# nrf7140_wificore register map
Vendor: Nordic Semiconductor; Series: nRF71; File version: 1
Registers are 32-bit, read-write, reset 0x0 unless marked. A register's access mark holds for its fields unless they carry their own. Offsets are from the block's base; [hi:lo] are bit positions; lines under a group give offsets from that group; {n}, {i} and the like mark numbered series; 'fields as' and 'values as' point back to an identical list; <NAME> marks a mode.

## RPUPHY (part 7 of 8) — WIFICore RPU PHY peripherals
Base 0x48080000; alternate view of RPUMAC
0x11000 TXSCP group — Unspecified
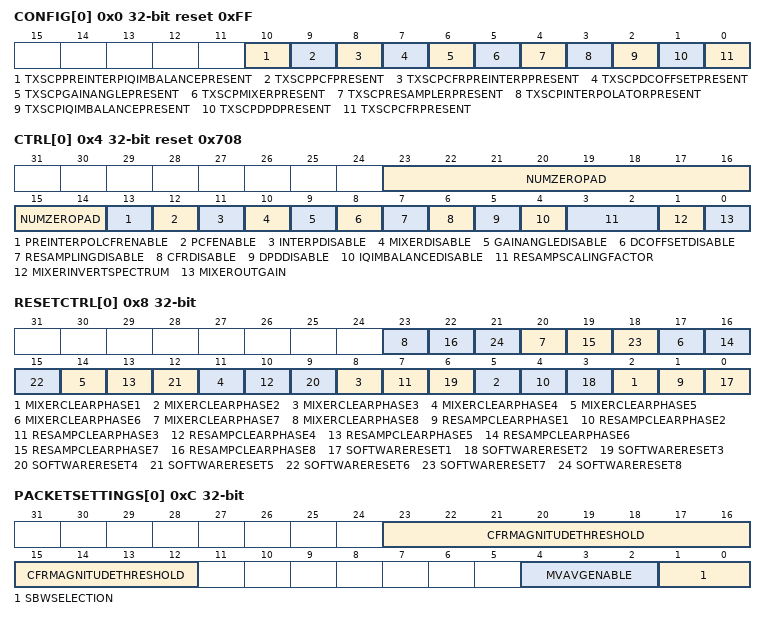
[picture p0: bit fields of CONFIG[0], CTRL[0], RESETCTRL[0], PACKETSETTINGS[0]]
  {0x0+4j} CONFIG[{j}] (j=0..0) ro reset 0xFF — Description collection: TXSCP CONFIG
    [10] TXSCPPREINTERPIQIMBALANCEPRESENT — This is a read-only field. Value read out indicates the presence of the pre interpolator IQ Imbalance block in the TX SCP.0: Pre interpolator IQ Imbalance not present.1: Pre interpolator IQ Imbalance present.Writing to field would not change its value.
    [9] TXSCPPCFPRESENT — This is a read-only field. Value read out indicates the presence of the PCF block in the TX SCP.0: PCF not present.1: PCF present.Writing to field would not change its value.
    [8] TXSCPCFRPREINTERPPRESENT — This is a read-only field. Value read out indicates the presence of the pre interpolator block in the TX SCP.0: Pre interpolator not present.1: Pre interpolator present.Writing to field would not change its value.
    [7] TXSCPDCOFFSETPRESENT — This is a read-only field. Value read out indicates the presence of the DC Offset block in the TX SCP.0: DC Offset not present.1: DC Offset present.Writing to field would not change its value.
    [6] TXSCPGAINANGLEPRESENT — This is a read-only field. Value read out indicates the presence of the Gain Angle block in the TX SCP.0: Gain Angle not present.1: Gain Angle present.Writing to field would not change its value.
    [5] TXSCPMIXERPRESENT — This is a read-only field. Value read out indicates the presence of the Mixer block in the TX SCP.0: Mixer not present.1: Mixer present.Writing to field would not change its value.
    [4] TXSCPRESAMPLERPRESENT — This is a read-only field. Value read out indicates the presence of the Resampler block in the TX SCP.0: Resampler not present.1: Resampler present.Writing to field would not change its value.
    [3] TXSCPINTERPOLATORPRESENT — This is a read-only field. Value read out indicates the presence of the Interpolator block in the TX SCP.0: Interpolator not present.1: Interpolator present.Writing to field would not change its value.
    [2] TXSCPIQIMBALANCEPRESENT — This is a read-only field. Value read out indicates the presence of the IQ imbalance block in the TX SCP.0: IQ imbalance not present.1: IQ imbalance present.Writing to field would not change its value.
    [1] TXSCPDPDPRESENT — This is a read-only field. Value read out indicates the presence of the DPD block in the TX SCP.0: DPD not present.1: DPD present.Writing to field would not change its value.
    [0] TXSCPCFRPRESENT — This is a read-only field. Value read out indicates the presence of the CFR block in the TX SCP.0: CFR not present.1: CFR present.Writing to field would not change its value.
  {0x4+4j} CTRL[{j}] (j=0..0) reset 0x708 — Description collection: TXSCP CTRL
    [23:14] NUMZEROPAD — Number of padding zeros to add to the input at the end of the packet.
    [13] PREINTERPOLCFRENABLE — Used to set the bypass mode of the pre interpolator CFR in TX-SCP block:
      0=Pre interpolator CFR is powered down and data passes around it unaltered; 1=PreInterpolatorCfrIs1 (Pre interpolator CFR is active.)
    [12] PCFENABLE — Used to set the bypass mode of the PCF in TX-SCP block:
      0=PCF is powered down and data passes around it unaltered; 1=PcfIsActive
    [11] INTERPDISABLE — Used to set the bypass mode of the interpolator in TX-SCP block:
      0=Interpolator is active (Interpolation factor I = 2); 1=Interpolator is powered down. Data passes around it unaltered (Interpolation factor I = 1).
    [10] MIXERDISABLE — Used to set the bypass mode of the Mixer block:
      0=MixerBlockIsActive; 1=Mixer block is powered down and data passes around it unaltered
    [9] GAINANGLEDISABLE — Used to set the bypass mode of the Gain Angle block:
      0=Gain Angle block is active; 1=Gain Angle block is powered down and data passes around it unaltered
    [8] DCOFFSETDISABLE — Used to set the bypass mode of the DC Offset block:
      0=DC Offset block is active; 1=DC Offset block is powered down and data passes around it unaltered
    [7] RESAMPLINGDISABLE — Used to set the bypass mode for the resampling operation:
      0=Resampling operation active; 1=Resampling operation powered down. The input data to the resampler is sent unaltered to the Mixer.
    [6] CFRDISABLE — Used to set the bypass mode of the CFR block:
      0=CfrIsActive; 1=CFR is powered down and data passes around it unaltered
    [5] DPDDISABLE — Used to set the bypass mode of the DPD block:
      0=DpdIsActive; 1=DPD is powered down and data passes around it unaltered
    [4] IQIMBALANCEDISABLE — Used to set the bypass mode of the IQ imbalance compensation block:
      0=IQ imbalance compensation is active; 1=IQ imbalance compenstation block is powered down and data passes around it unaltered
    [3:2] RESAMPSCALINGFACTOR — X8 output scaled by a factor of:
      0=025; 1=050; 2=100; 3=200
    [1] MIXERINVERTSPECTRUM — Selects Mixer spectrum inversion:0: The mixer output spectrum is not inverted.1: The mixer output spectrum is inverted by swapping I and Q.The mixer design under normal operation inverts the output I and Q samples even if this field is set to 0. To re-invert set field to 1.Relevant when MIXER_DISABLE = 0.
    [0] MIXEROUTGAIN — Selects Mixer output gain:0: Gain of 1.0 is applied to the output of Mixer rotator (default).1: Gain of 2.0 is applied to the output of Mixer rotator (used to compensate for 0.5 gain in real input mode).Relevant when MIXER_DISABLE = 0.
  {0x8+4j} RESETCTRL[{j}] (j=0..0) — Description collection: TXSCP RESET CTRL
    [3n-1] MIXERCLEARPHASE{n} (n=1..8) — Clears Mixer_{n} phase:0: Mixer phase accumulators run normally.1: Mixer phase accumulators are forced to zero.Relevant when MIXER_DISABLE = 0.
    [3n-2] RESAMPCLEARPHASE{n} (n=1..8) — Clears Resampler_{n} phase:0: Resampler phase accumulators run normally.1: Resampler phase accumulators are forced to zero.Relevant when RESAMPLING_DISABLE = 0.
    [3n-3] SOFTWARERESET{n} (n=1..8) — Software reset for TX-SCP{n}.
      0=NormalOperation; 1=ResetAsserted
  {0xC+4j} PACKETSETTINGS[{j}] (j=0..0) — Description collection: TXSCP PACKET SETTINGS
    [23:12] CFRMAGNITUDETHRESHOLD — Clipping threshold for CFR module with CORDIC gain compensated i.e A/gain_codic
    [4:2] MVAVGENABLE — Used to enable the post-resampler moving average filter:0: post-RS filter is powered down and data passes around it unaltered.1: post-RS moving average filter with 2 tap is enabled.2: post-RS moving average filter with 4 tap is enabled.3: post-RS moving average filter with 8 tap is enabled.4: post-RS moving average filter with 12 tap is enabled.5: post-RS moving average filter with 16 tap is enabled.6-7: Reserved.
    [1:0] SBWSELECTION — Represents the index of SBW parameter set. This index is used to select the SBW parametersfrom one of the four sets.
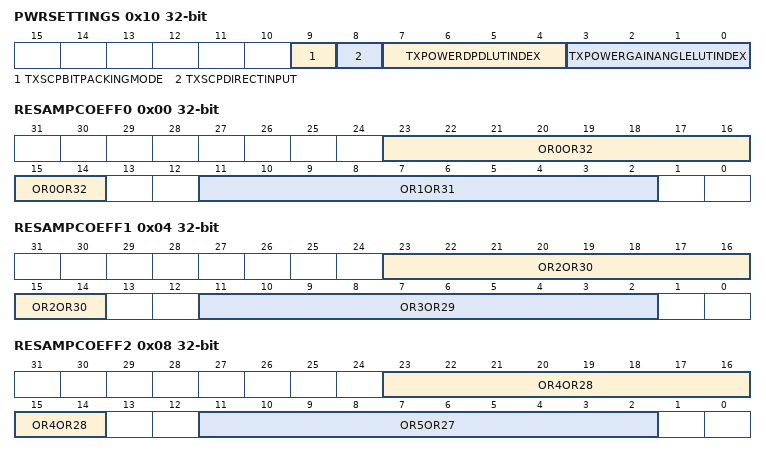
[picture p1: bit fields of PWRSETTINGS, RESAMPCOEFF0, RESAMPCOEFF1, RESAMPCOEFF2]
  0x10 PWRSETTINGS — TXSCP PWR SETTINGS
    [9] TXSCPBITPACKINGMODE — In packing mode, Converts 12-bit real and img phase inputs (at in[15:4]) to a 24-bit output with real in out[23:12] and img in out[11:0]
      0=StandardMode; 1=PackingMode
    [8] TXSCPDIRECTINPUT — Selects whether TXSCP input comes from previous pipeline stage or EDC (tbus).
      0=Tbus; 1=Direct
    [7:4] TXPOWERDPDLUTINDEX — TX power index of DPD LUT of TXSCP. This index is used to pick power dependent DPD coefficients from the DPD LUT.
    [3:0] TXPOWERGAINANGLELUTINDEX — TX power index of Gain Angle LUT of TXSCP. This index is used to pick power dependent gain/angle coefficients fromthe Gain Angle LUT.
  {0x14+0x24*j} TXSCPRESAMPCOEFF[{j}] (j=0..0) group — Unspecified
    0x00 RESAMPCOEFF0 — Description cluster: TXSCP RESAMP COEFF0
      [23:14] OR0OR32 — Coefficient of resampler filter in 2's complement format with range -1 to +1.Relevant when RESAMPLING_DISABLE = 0.
      [11:2] OR1OR31 — Coefficient of resampler filter in 2's complement format with range -1 to +1.Relevant when RESAMPLING_DISABLE = 0.
    0x04 RESAMPCOEFF1 — Description cluster: TXSCP RESAMP COEFF1
      [23:14] OR2OR30 — Coefficient of resampler filter in 2's complement format with range -1 to +1.Relevant when RESAMPLING_DISABLE = 0.
      [11:2] OR3OR29 — Coefficient of resampler filter in 2's complement format with range -1 to +1.Relevant when RESAMPLING_DISABLE = 0.
    0x08 RESAMPCOEFF2 — Description cluster: TXSCP RESAMP COEFF2
      [23:14] OR4OR28 — Coefficient of resampler filter in 2's complement format with range -1 to +1.Relevant when RESAMPLING_DISABLE = 0.
      [11:2] OR5OR27 — Coefficient of resampler filter in 2's complement format with range -1 to +1.Relevant when RESAMPLING_DISABLE = 0.
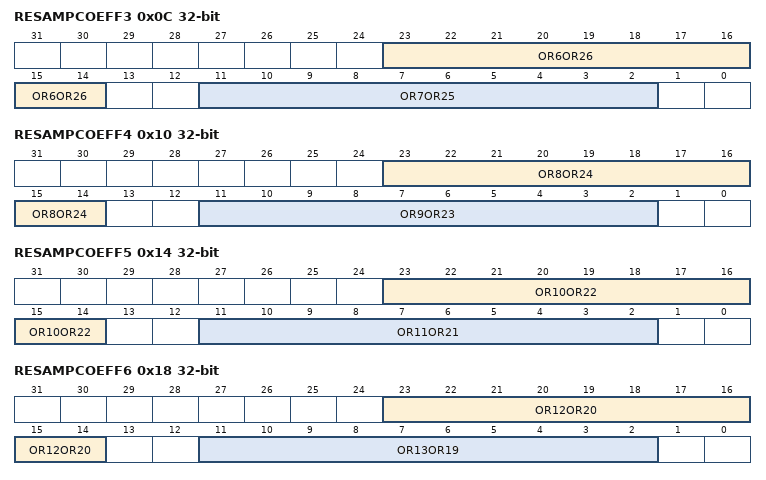
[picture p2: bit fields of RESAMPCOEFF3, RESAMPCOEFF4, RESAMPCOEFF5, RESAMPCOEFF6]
    0x0C RESAMPCOEFF3 — Description cluster: TXSCP RESAMP COEFF3
      [23:14] OR6OR26 — Coefficient of resampler filter in 2's complement format with range -1 to +1.Relevant when RESAMPLING_DISABLE = 0.
      [11:2] OR7OR25 — Coefficient of resampler filter in 2's complement format with range -1 to +1.Relevant when RESAMPLING_DISABLE = 0.
    0x10 RESAMPCOEFF4 — Description cluster: TXSCP RESAMP COEFF4
      [23:14] OR8OR24 — Coefficient of resampler filter in 2's complement format with range -1 to +1.Relevant when RESAMPLING_DISABLE = 0.
      [11:2] OR9OR23 — Coefficient of resampler filter in 2's complement format with range -1 to +1.Relevant when RESAMPLING_DISABLE = 0.
    0x14 RESAMPCOEFF5 — Description cluster: TXSCP RESAMP COEFF5
      [23:14] OR10OR22 — Coefficient of resampler filter in 2's complement format with range -1 to +1.Relevant when RESAMPLING_DISABLE = 0.
      [11:2] OR11OR21 — Coefficient of resampler filter in 2's complement format with range -1 to +1.Relevant when RESAMPLING_DISABLE = 0.
    0x18 RESAMPCOEFF6 — Description cluster: TXSCP RESAMP COEFF6
      [23:14] OR12OR20 — Coefficient of resampler filter in 2's complement format with range -1 to +1.Relevant when RESAMPLING_DISABLE = 0.
      [11:2] OR13OR19 — Coefficient of resampler filter in 2's complement format with range -1 to +1.Relevant when RESAMPLING_DISABLE = 0.
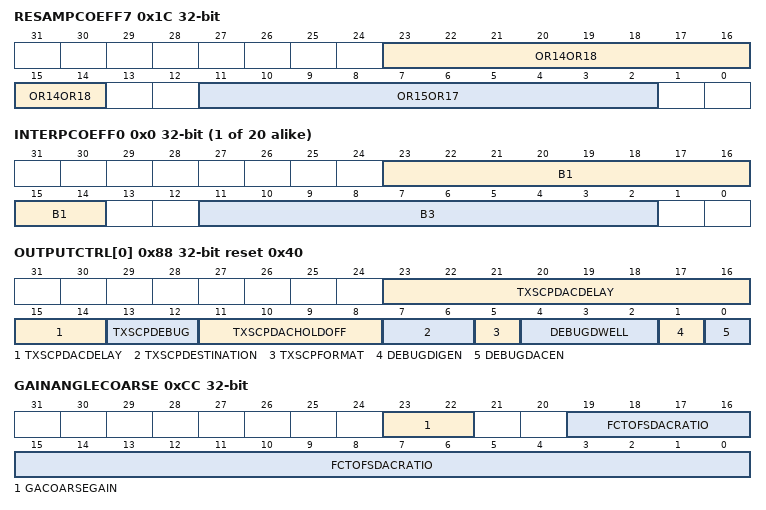
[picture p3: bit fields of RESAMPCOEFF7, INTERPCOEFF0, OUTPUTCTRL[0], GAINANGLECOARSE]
    0x1C RESAMPCOEFF7 — Description cluster: TXSCP RESAMP COEFF7
      [23:14] OR14OR18 — Coefficient of resampler filter in 2's complement format with range -1 to +1.Relevant when RESAMPLING_DISABLE = 0.
      [11:2] OR15OR17 — Coefficient of resampler filter in 2's complement format with range -1 to +1.Relevant when RESAMPLING_DISABLE = 0.
    0x20 RESAMPCOEFF8 — Description cluster: TXSCP RESAMP COEFF8
      [23:14] OR16 — Coefficient of resampler filter in 2's complement format with range -1 to +1.Relevant when RESAMPLING_DISABLE = 0.
  {0x38+0x14*j} TXSCPINTERPCOEFF[{j}] (j=0..3) group — Unspecified
    {0x0+4k} INTERPCOEFF{k} (k=0..4) — Description cluster: TXSCP INTERP COEFF{k}
      [23:14] B{4k+1} — Coefficient of interpolation filter in 2's complement format with range -1 to +1.Relevant when RESAMPLING_DISABLE = 0.
      [11:2] B{4k+3} — Coefficient of interpolation filter in 2's complement format with range -1 to +1.Relevant when RESAMPLING_DISABLE = 0.
  {0x88+4j} OUTPUTCTRL[{j}] (j=0..0) reset 0x40 — Description collection: TXSCP OUTPUT CTRL
    [23:14] TXSCPDACDELAY — Specifies the number of DAC clock cycles to delay the DAC output after a reset.
    [13:12] TXSCPDEBUG — Enable flow control debug registers TXSCP_SAMPLE_I_EXT and TXSCP_SAMPLE_Q_EXT
      0=Disabled; 1=ValidEnable; 2=Sticky(Valid), Sticky(Enable); 3=Valid & Enable, Sticky(Valid & Enable)
    [11:8] TXSCPDACHOLDOFF — Specifies the number of DAC clock cycles to hold-off the DAC output to allow the synchroniser to fill.
    [7:6] TXSCPDESTINATION — Selects the destination of the resampler output:
      0=Destination is TXSCP TBus Rd port; 1=Destination is on-board DAC; 2=Destination is TXSCP_SAMPLE register; 3=Reserve (This is reserved.)
    [5] TXSCPFORMAT — Specifies the output sample format as follows:
      0=2SComplementSamples; 1=OffsetBinarySamples
    [4:2] DEBUGDWELL — Specifies the number of times that each output sample is repeated.If the output sequence is A, B, C, D, ... then the DAC/Debug sample sequence is :DWELL=0 :A, B, C, D, ...DWELL=1 :A, A, B, B, C, C, D, D,...' ' ' ''DWELL=7 :A, A,A,A, A,A,A,A, B, B, B, ,...
    [1] DEBUGDIGEN — Enables the digital debug port:
      0=The digital debug output port is disabled; 1=TheDigitalDebugOutpu1 (The digital debug output port is enabled.)
    [0] DEBUGDACEN — Enables the DAC port:Note For the DAC output port to operate correctly, DBG_DIGEN must be set to 0.
      0=The DAC output port is disabled; 1=The DAC output port is enabled
  {0x8C+0x10*j} TXSCPSBWPARAM[{j}] (j=0..3) group — Unspecified
    0x00 BASEVAL reset 0x800000 — Description cluster: TXSCP BASE VAL
      [23:21] TXSCPBASE — Peripheral resampling factor base. This is an unsigned value which is combined with the 2's complement TXSCP_CONTROL to generate the 26-bit control FsO:FsO = (TXSCP_BASE << 23) + TXSCP_CONTROLFsO is the sample conversion ratio (I / O) used in the requirements section of the TX-SCP. FsO is an unsigned number, where the full-scale value represents a ratio of 1.999999.In normal operation, FsO is expected to take values in the range 0.0 to 1.9999. The larger number range provided here may be useful for system testing.Note: To convert a ratio into the 26-bit FsO, multiply by 2^25.Relevant when RESAMPLING_DISABLE = 0.
    0x04 FACTORVAL — Description cluster: TXSCP FACTOR VAL
      [23:0] TXSCPCONTROL — Resampling factor control. This is a 2's complement value which is combined with TXSCP_BASE to generate the 28-bit control FsO:FsO = (TXSCP_BASE << 23) + TXSCP_CONTROLRelevant when RESAMPLING_DISABLE = 0.
    0x08 MIXERLOBASE — Description cluster: TXSCP MIXER LO BASE
      [23:21] MIXLOBASE — Local Oscillator base. This is a 2's complement value which is combined with LO_CONTROL to generate the 26-bit control Fc:Fc = (LO_BASE << 23) + LO_CONTROLFc is in 2's complement signed format where its value represents numbers within the range -1 to 0.9999999. To convert a ratio into the 26-bit Fc, multiply by 2^25.The digitally generated Local Oscillator (LO) frequency used in the mixer section is equal to Fc * (IF Clock Frequency/2).Hence the full-scale negative value represents a frequency of -(IF Clock Frequency/2).The input signal is frequency translated such that input frequency F moves to a frequency of F + Local Oscillator (LO) Frequency.Relevant when MIXER_DISABLE = 0.
    0x0C MIXERLOCONTROL — Description cluster: TXSCP MIXER LO CONTROL
      [23:0] MIXLOCONTROL — Local Oscillator control. This is a 2's complement value which is combined with LO_BASE to generate the 26-bit control Fc:Fc = (LO_BASE << 23) + LO_CONTROLRelevant when MIXER_DISABLE = 0.
  0xCC GAINANGLECOARSE — TXSCP GAIN ANGLE COARSE
    [23:22] GACOARSEGAIN — Selects coarse gain applied in the gain angle block:00: I and Q outputs are (multiplier result >> 8).01: I and Q outputs are (multiplier result >> 10).10: I and Q outputs are (multiplier result >> 6).11: Reserved.Relevant when GAIN_ANGLE_DISABLE = 0.
    [19:0] FCTOFSDACRATIO — This field represents ratio of mixer-center-frequency to DAC-sampling frequency. It is in unsigned 8.12 format.
  {0xD0+0xC*j} TXSCPGAINANGLE[{j}] (j=0..12) group — Unspecified
    0x00 GAINANGLEFINEI reset 0x200000 — Description cluster: TXSCP GAIN ANGLE FINE I
      [23:13] GAIGAIN — 2's complement value that multiplies I value from mixer. This is a linear gain where 0x100 represents the 0dB point, thus the gain is I_GAIN/0x100.Relevant when GAIN_ANGLE_DISABLE = 0.
    0x04 GAINANGLEFINEQ reset 0x200000 — Description cluster: TXSCP GAIN ANGLE FINE Q
      [23:13] GAQGAIN — 2's complement value that multiplies Q value from mixer. This is a linear gain where 0x100 represents the 0dB point, thus the gain is Q_GAIN/0x100.Relevant when GAIN_ANGLE_DISABLE = 0.
    0x08 GAINANGLEIQ — Description cluster: TXSCP GAIN ANGLE IQ
      [23:13] GAITOQGAIN — 2's complement value that multiplies I value before addition to Q value in the gain angle block.Qout = Q + (I * I_TO_Q_GAIN >> 10)Relevant when GAIN_ANGLE_DISABLE = 0.
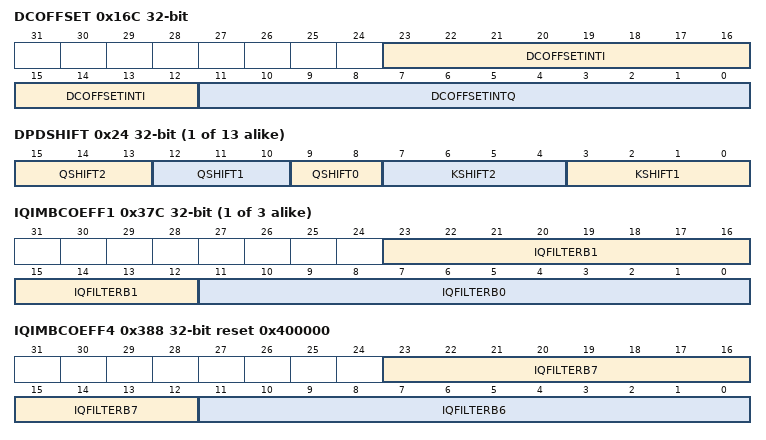
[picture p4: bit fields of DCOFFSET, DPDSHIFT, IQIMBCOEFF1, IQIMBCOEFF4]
  0x16C DCOFFSET — TXSCP DC OFFSET
    [23:12] DCOFFSETINTI — This field represents the 12 integer bits (23:12) of DC offset cancellation value for the I channel. The DC offset for the I channel is a 2's complement value with12 integer bits (23:12) and 12 fractional bits (11:0).Relevant when DC_OFFSET_DISABLE = 0.
    [11:0] DCOFFSETINTQ — This field represents the 12 integer bits (23:12) of DC offset cancellation value for the Q channel. The DC offset for the Q channel is a 2's complement value with12 integer bits (23:12) and 12 fractional bits (11:0).Relevant when DC_OFFSET_DISABLE = 0.
  {0x170+0x28*j} TXSCPDPDCOEFF[{j}] (j=0..12) group — Unspecified
    0x00 DPDCOEFF10 — Description cluster: TXSCP DPD COEFF10
      [23:0] DPDCOEFFA10 — DPD Coefficient A10. Relevant when DPD_DISABLE = 0.
    0x04 DPDCOEFF20 — Description cluster: TXSCP DPD COEFF20
      [23:0] DPDCOEFFA20 — DPD Coefficient A20. Relevant when DPD_DISABLE = 0.
    0x08 DPDCOEFF30 — Description cluster: TXSCP DPD COEFF30
      [23:0] DPDCOEFFA30 — DPD Coefficient A30. Relevant when DPD_DISABLE = 0.
    0x0C DPDCOEFF11 — Description cluster: TXSCP DPD COEFF11
      [23:0] DPDCOEFFA11 — DPD Coefficient A11. Relevant when DPD_DISABLE = 0.
    0x10 DPDCOEFF21 — Description cluster: TXSCP DPD COEFF21
      [23:0] DPDCOEFFA21 — DPD Coefficient A21. Relevant when DPD_DISABLE = 0.
    0x14 DPDCOEFF31 — Description cluster: TXSCP DPD COEFF31
      [23:0] DPDCOEFFA31 — DPD Coefficient A31. Relevant when DPD_DISABLE = 0.
    0x18 DPDCOEFF12 — Description cluster: TXSCP DPD COEFF12
      [23:0] DPDCOEFFA12 — DPD Coefficient A12. Relevant when DPD_DISABLE = 0.
    0x1C DPDCOEFF22 — Description cluster: TXSCP DPD COEFF22
      [23:0] DPDCOEFFA22 — DPD Coefficient A22. Relevant when DPD_DISABLE = 0.
    0x20 DPDCOEFF32 — Description cluster: TXSCP DPD COEFF32
      [23:0] DPDCOEFFA32 — DPD Coefficient A32. Relevant when DPD_DISABLE = 0.
    0x24 DPDSHIFT — Description cluster: TXSCP DPD SHIFT
      [15:13] QSHIFT2 — Variable Shifting at the output of the complex multiplier, Q=2
      [12:10] QSHIFT1 — Variable Shifting at the output of the complex multiplier, Q=1
      [9:8] QSHIFT0 — Variable Shifting at the output of the complex multiplier, Q=0
      [7:4] KSHIFT2 — Variable Shifting at the output of the mixed multiplier, K=3
      [3:0] KSHIFT1 — Variable Shifting at the output of the mixed multiplier, K=2
  0x378 IQIMBINPHASEDLY reset 0x7 — TXSCP IQ IMB INPHASE DLY
    [3:0] IQINPHASEDELAY — Delay line for Inphase stream. This is a unsigned value.The maximum supported value is 14.Relevant when IQ_IMBALANCE_DISABLE = 0.
  {0x378+4j} IQIMBCOEFF{j} (j=1..3) — TXSCP IQ IMB COEFF{j}
    [23:12] IQFILTERB{2j-1} — Filter Coefficient B{2j-1} for Quadrature phase stream. This is a Q10 format (i.e. output of filter is right-shifted by 10 bits) 2's complement value.Relevant when IQ_IMBALANCE_DISABLE = 0.
    [11:0] IQFILTERB{2j-2} — Filter Coefficient B{2j-2} for Quadrature phase stream. This is a Q10 format (i.e. output of filter is right-shifted by 10 bits) 2's complement value.Relevant when IQ_IMBALANCE_DISABLE = 0.
  0x388 IQIMBCOEFF4 reset 0x400000 — TXSCP IQ IMB COEFF4
    [23:12] IQFILTERB7 — Filter Coefficient B7 for Quadrature phase stream. This is a Q10 format (i.e. output of filter is right-shifted by 10 bits) 2's complement value.Relevant when IQ_IMBALANCE_DISABLE = 0.
    [11:0] IQFILTERB6 — Filter Coefficient B6 for Quadrature phase stream. This is a Q10 format (i.e. output of filter is right-shifted by 10 bits) 2's complement value.Relevant when IQ_IMBALANCE_DISABLE = 0.
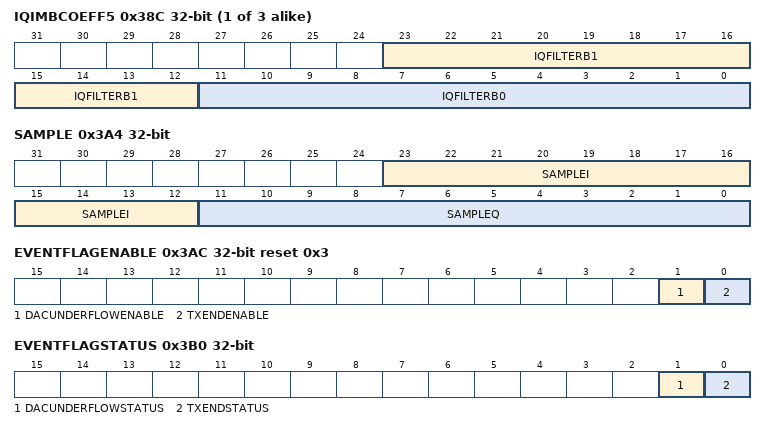
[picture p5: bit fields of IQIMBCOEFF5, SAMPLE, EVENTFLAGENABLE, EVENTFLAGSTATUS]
  {0x378+4j} IQIMBCOEFF{j} (j=5..7) — TXSCP IQ IMB COEFF{j}
    fields as TXSCP.IQIMBCOEFF1
  0x398 IQIMBCOEFF8 — TXSCP IQ IMB COEFF8
    [11:0] IQFILTERB14 — Filter Coefficient B14 for Quadrature phase stream. This is a Q10 format (i.e. output of filter is right-shifted by 10 bits) 2's complement value.Relevant when IQ_IMBALANCE_DISABLE = 0.
  0x39C DACUNDERFLOWFLAG — TXSCP DAC UNDERFLOW FLAG
    [0] DACUNDERFLOWFLAG — This register is set to '1' if no valid data present on the DAC output, once data has started to flow out through it. To reset this flag write any value to the register.Note that the behaviour of this register is different from the similarly-named DAC_UNDERFLOW event flag available in TXSCP_EVENT_FLAG_STATUS.Setting DAC_UNDERFLOW_CLEAR will also clear this register.
  0x3A0 MIXERDEBUGFCACCUM ro — TXSCP MIXER DEBUG FCACCUM
    [23:0] MIXDEBUGFCACCUM — This is a read only register and provides the fcaccum value from the mixer for debug purposes.Relevant when MIXER_DISABLE = 0.
  0x3A4 SAMPLE — TXSCP SAMPLE
    [23:12] SAMPLEI — In phase output sample. Valid when SAMPLE_VALID = 1. Write any value to this register to acknowledge sample has been read, this will not overwrite the resampler output.
    [11:0] SAMPLEQ — Quadrature output sample. Valid when SAMPLE_VALID = 1. Write any value to this register to acknowledge sample has been read, this will not overwrite the resampler output.
  0x3A8 SAMPLEVALID — TXSCP SAMPLE VALID
    [0] SAMPLEVALID — Output sample valid. Software must poll for SAMPLE_VALID = 1 before reading SAMPLE_I or SAMPLE_Q.
  0x3AC EVENTFLAGENABLE reset 0x3 — TXSCP EVENT FLAG ENABLE
    [1] DACUNDERFLOWENABLE — DAC Underflow Event Flag Enable
    [0] TXENDENABLE — TX End Event Flag Enable
  0x3B0 EVENTFLAGSTATUS — TXSCP EVENT FLAG STATUS
    [1] DACUNDERFLOWSTATUS — This flag is set to '1' if no valid data present on the DAC output, once data has started to flow out through it. This will ONLY be set if the DAC underflow occurs before the TX_END event flag is set.Note that the behaviour of this flag is different from the TXSCP_DAC_UNDERFLOW_FLAG register, which has no dependence on TX_END.
    [0] TXENDSTATUS — This flag is set to '1' after the last sample of the transmit packet has been written to the DAC output.
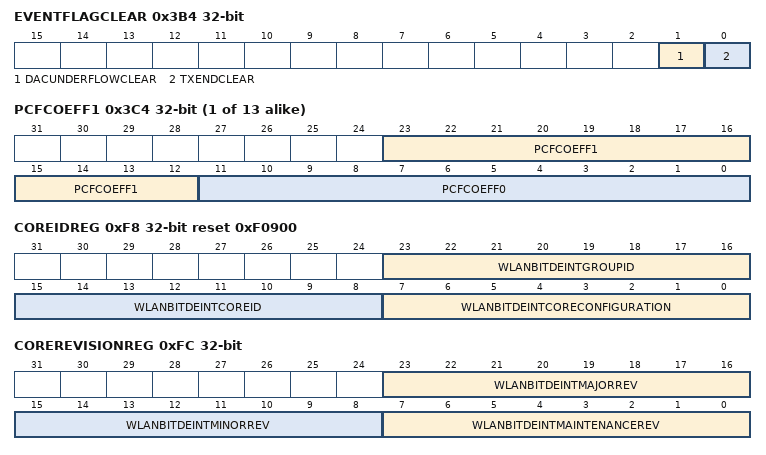
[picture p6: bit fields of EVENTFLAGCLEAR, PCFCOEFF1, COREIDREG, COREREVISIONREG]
  0x3B4 EVENTFLAGCLEAR — TXSCP EVENT FLAG CLEAR
    [1] DACUNDERFLOWCLEAR — DAC Underflow Event Flag Clear
    [0] TXENDCLEAR — TX End Event Flag Clear
  0x3B8 SAMPLEIEXT ro — TXSCP SAMPLE I EXT
    [15:0] SAMPLEIEXT — When TXSCP_DEBUG=0: In phase output sample. Valid when SAMPLE_VALID = 1. To acknowledge sample has been read, write any value to TXSCP_SAMPLE register.When TXSCP_DEBUG=1: Live state of the valid flow control signals0: TX-SCP WR1: Pre-Interpolalation CFR Input2: Pre-Interpolalation CFR Output3: Interpolalation Filter Output4: Post-Interpolalation CFR Output5: Resampler CFR Output6: Mixer Output7: DPD Output8: Gain Angle Output9: IQ Imbalance Output10: Phase Compensation Filter Output11: DC Offset Output12: Synchroniser Input13: Synchroniser Output Pre-Holdoff14: Synchroniser Output Post-Holdoff15: Pre-interpolation IQ Imbalance
  0x3BC SAMPLEQEXT ro — TXSCP SAMPLE Q EXT
    [15:0] SAMPLEQEXT — When TXSCP_DEBUG=0: Quadrature output sample. Valid when SAMPLE_VALID = 1. To acknowledge sample has been read, write any value to TXSCP_SAMPLE register.When TXSCP_DEBUG=1: Live state of the enable flow control signals0: TX-SCP WR1: Pre-Interpolalation CFR Input2: Pre-Interpolalation CFR Output3: Interpolalation Filter Output4: Post-Interpolalation CFR Output5: Resampler CFR Output6: Mixer Output7: DPD Output8: Gain Angle Output9: IQ Imbalance Output10: Phase Compensation Filter Output11: DC Offset Output12: Synchroniser Input13: Synchroniser Output Pre-Holdoff14: Synchroniser Output Post-Holdoff15: Pre-interpolation IQ Imbalance
  {0x3C0+4j} PACKETSETTINGS2[{j}] (j=0..0) — Description collection: TXSCP PACKET SETTINGS2
    [11:0] PREINTERPCFRMAGTHRESHOLD — Threshold for CFR block prior to interpolation filter.
  {0x3C0+4j} PCFCOEFF{j} (j=1..13) — TXSCP PCF COEFF{j}
    [23:12] PCFCOEFF{2j-1} — Filter Coefficient {2j-1} for PCF. This is a 12-bit 2s complement value. Relevant when PCF_ENABLE = 1.
    [11:0] PCFCOEFF{2j-2} — Filter Coefficient {2j-2} for PCF. This is a 12-bit 2s complement value. Relevant when PCF_ENABLE = 1.
  0x3F8 PCFCOEFF14 — TXSCP PCF COEFF14
    [11:0] PCFCOEFF26 — Filter Coefficient 26 for PCF. This is a 12-bit 2s complement value. Relevant when PCF_ENABLE = 1.
  0x3FC PCFSHIFT — TXSCP PCF SHIFT
    [2:0] PCFSHIFT — Variable Shifting at the output of the PCF.
0x12000 WLAN_BIT_DEINT group — Unspecified
  0x00 CONFIG00 — WLAN BIT DEINT CONFIG 00
    [2:0] CONFIGMODULATION — Specify the modulation of the LLR data being processed by the Wireless LAN Bit Deinterleaver.Valid values are below.Other values are reserved and should not be used.
      0=BPSK (Constellation size M = 2) (Nbpsc = 1, 1 LLRper data word); 1=QPSK (Constellation size M = 4) (Nbpsc = 2, 1 LLRper data word); 2=16-QAM (Constellation size M =16) (Nbpsc = 4, 2 LLRs per data word); 3=64-QAM (Constellation size M =64) (Nbpsc = 6, 3 LLRs per data word); 4=256-QAM (Constellation size M = 256) (Nbpsc = 8, 4 LLRs per data word)
  0x04 CONFIG01 — WLAN BIT DEINT CONFIG 01
    [4:0] CONFIGNROWS — Specifies the number of active Rows the Bit Deinterleaver should use when processing LLR data.Note that each element in a row contains 4 sub-elements, where each sub-element holds one LLR.The number of LLRs stored in a Row element varies based on the modulation scheme in use.Valid values are below.Other values are reserved and should not be used.Legacy: 3 (BPSK) or6 (non-BPSK)HT/VHT 20 MHz:4 (BPSK) or8 (non-BPSK)HT/VHT 40 MHz:6 (BPSK) or 12 (non-BPSK)VHT80 MHz:9 (BPSK) or 18 (non-BPSK)
  0x08 CONFIG02 — WLAN BIT DEINT CONFIG 02
    [4:0] CONFIGNCOLS — Specifies the number of active Columns the Bit Deinterleaver should use when processing LLR data.Valid values are below.Other values are reserved and should not be used.Legacy: 16HT/VHT 20 MHz:13HT/VHT 40 MHz:18VHT80 MHz:26Note that the maximum number of columns is 18 when BUILD_WLAN_AC = 0.
  0x0C CONFIG03 — WLAN BIT DEINT CONFIG 03
    [4:0] CONFIGINIROWOFFSET — Initial Row Offset.This is the row in which the first element of LLRs are written.Note that a Row is made up of elements, each of which holds four sub-elements capable of storing one LLR.Note 1. CONFIG_INI_ROW_OFFSET has the range 0 to CONFIG_N_ROWS-1Note 2. If the value in this register is non-zero then registers CONFIG_INI_WRITE_POINTER and CONFIG_INI_ROW_SWAP_TYPE should be configured appropriately.Note 3. The value in this register is derived from the Row Offset equation, see section 2.4.1 (Bit Deinterleaver Stage one (Frequency rotation)) for the RowOffset formula.Where Row Offset in this register is the value from the RowOffset equation divided by S.Note 4. S defines the number of LLRs stored in each element of the BDI buffer grid for the current modulation scheme.S is defined as: S=Max((log2(M)/2),1) or S=Max(Nbpsc/2),1)Where M (Constellation size) and Nbpsc are defined in the description for register CONFIG_MODULATION
  0x10 CONFIG04 — WLAN BIT DEINT CONFIG 04
    [4:0] CONFIGINICOLOFFSET — Initial Column index.This is the column in which the first LLR is written.Note that a column is made up of elements, each of which holds four sub-elements capable of storing one LLR.Note 1. CONFIG_INI_COL_OFFSET has the range 0 to CONFIG_N_COLS-1.Note 2. If the value in this register is non-zero then registers CONFIG_INI_WRITE_POINTER and CONFIG_INI_ROW_SWAP_TYPE should be configured appropriately.
  0x14 CONFIG05 — WLAN BIT DEINT CONFIG 05
    [8:0] CONFIGBUFFERSIZE — This register specifies the number of buffer storage elements required for the Bit Deinterleaver operation.Note that an element consists of four sub-elements each capable of storing one LLR.It is defined as CONFIG_N_ROWS multiplied by CONFIG_N_COLS.The value in this register is ONLY valid when it is derived from valid values in CONFIG_N_ROWS and CONFIG_N_COLS.Other values are not valid and must not be used.When register CONFIG_USE_AS_BUFFER = 1 the usage of this register is relaxed - this is described further in the description of register CONFIG_USE_AS_BUFFER.
  0x18 CONFIG06 — WLAN BIT DEINT CONFIG 06
    [8:0] CONFIGINIWRITEPOINTER — This register specifies the initial value of the write pointer for writing the first element of LLR data into the write buffer.The value in this register is calculated as follows:((CONFIG_INI_ROW_OFFSET * CONFIG_N_COLS) + CONFIG_INI_COL_OFFSET)Note 1. Check the descriptions of CONFIG_INI_ROW_OFFSET and CONFIG_INI_COL_OFFSET for further notes on the values in these registers.Note 2. Note that row swapping may be required by the data being written into the elements of the write buffer.This row swapping is performed by the logic in the Bit Deinterleaver and does not need to be accounted for in this register, since this register defines the first write element, and not the organisation of the LLR data within that element.
  0x1C CONFIG07 — WLAN BIT DEINT CONFIG 07
    [1:0] CONFIGINIROWSWAPTYPE — This register is used to specify the row swapping type in use in the column CONFIG_INI_COL_OFFSET.It is only used when the modulation, set in register CONFIG_MODULATION, is set to a modulation scheme that requires row swapping - i.e. not BPSK (Nbpsc = 1) or QPSK (Nbpsc = 2).The value in this register is calculated as follows:For16-QAM (Nbpsc = 4): CONFIG_INI_COL_OFFSET percent2i.e. 0x0 when CONFIG_INI_COL_OFFSET is an even number0x1 when CONFIG_INI_COL_OFFSET is an odd numberFor64-QAM (Nbpsc = 6): CONFIG_INI_COL_OFFSET percent3i.e. 0x0 when CONFIG_INI_COL_OFFSET is 0,3,6, 9,12,etc0x1 when CONFIG_INI_COL_OFFSET is 1,4,7,10,13,etc0x2 when CONFIG_INI_COL_OFFSET is 2,5,8,11,14,etcFor 256-QAM (Nbpsc = 8): CONFIG_INI_COL_OFFSET percent4i.e. 0x0 when CONFIG_INI_COL_OFFSET is 0,4, 8,12,etc0x1 when CONFIG_INI_COL_OFFSET is 1,5, 9,13,etc0x2 when CONFIG_INI_COL_OFFSET is 2,6,10,14,etc0x3 when CONFIG_INI_COL_OFFSET is 3,7,11,15,etc
  0x20 CONFIG08 — WLAN BIT DEINT CONFIG 08
    [0] CONFIGUSEASBUFFER — This register is used to set the Deinterleaver into a buffer only mode.0x0: Operate as normal Bit Deinterleaver0x1: Operate as a Simple FIFO Buffer onlyWhen the Simple FIFO Buffer mode is selected the Bit Deinterleaver does not perform the usual Deinterleaving, but operates only as a FIFO buffer where both the write pointer and the read pointer use a linear incrementing address scheme.In this mode only the CONFIG_BUFFER_SIZE and CONFIG_MODULATION configuration registers are valid.The register CONFIG_BUFFER_SIZE should be set to the value of the required buffer size (columns multiplied by rows).The register CONFIG_MODULATION should be set with the modulation scheme of the current stream; this is used to determine the number of active LLRs in each LLR data word so that unused bytes can be masked to zero.Other configuration registers must not be used and should be set to zero.In the Simple FIFO Buffer mode the restrictions on the use of register CONFIG_BUFFER_SIZE are relaxed.Any value may be used in CONFIG_BUFFER_SIZE providing the value does NOT exceed the number of words available in the RAM instances (216 words for 802.11n and 472 words for 802.11ac).
  0xA0 TBUSOUTPUTMODE — WLAN BIT DEINT TBUS OUTPUT MODE
    [1] TBUSOUTPUTDISCARD — Set this register to '1' to discard the output from the T-Bus Read component that routes LLR data out from the Bit Deinterleaver to the T-Bus Port.This register will only discard output when register field TBUS_OUTPUT_MODE = 1 (i.e. when routing output LLR data to the P-Bus debug registers).
  0xB8 TBUSOUTPUTSIGNATURE ro reset 0xFFFFFF — WLAN BIT DEINT TBUS OUTPUT SIGNATURE
    [23:0] TBUSOUTPUTSIGNATURE — This register outputs a data signature from the T-Bus Output port driver.It is used for debug only.Reading from this register has no consequence.Writing to this Read Only register has no effect.
  0xF0 SWRESET — WLAN BIT DEINT SW RESET
    [23] SWRESET — Wireless LAN Bit Deinterleaver, Software Reset register SW_RESETThis register provides a means for resetting all the logic in the Wireless LAN Bit Deinterleaver block.The register is sticky so any reset has to be cleared manually.In other words, any reset applied with this register will NOT automatically clear; it must be manually cleared by writing '0' to this register.This software reset register will reset all logic in the Wireless LAN Bit Deinterleaver including:i. T-Bus Write port (LLR Input data)ii.T-Bus Read port (LLR Output data)iii. The Wireless LAN Bit Deinterleaver processing core (and all blocks within the core)iv.Top level Random StallersIt WILL NOT reset the wlan_bit_deint_regwrap Register Block Wrapper which includes the generated Register Bank.If the wlan_bit_deint_regwrap needs to be reset then the entire Wireless LAN Bit Deinterleaver must be reset using the software reset control in the UCCP_CORE registers.Alternatively a hardware reset can be performed.
      0=Clear block reset (default state); 1=Place and hold whole block in Reset
  0xF8 COREIDREG ro reset 0xF0900 — WLAN BIT DEINT CORE ID REG
    [23:16] WLANBITDEINTGROUPID — Identifies core as part of an IMG IP family group.[0x0F = UCC].
    [15:8] WLANBITDEINTCOREID — Identifies the member of the IP group. [0x09 = Wireless LAN Bit Deinterleaver (WLAN_BIT_DEINT)]
    [7:0] WLANBITDEINTCORECONFIGURATION — Configuration of the core.
  0xFC COREREVISIONREG ro — WLAN BIT DEINT CORE REVISION REG
    [23:16] WLANBITDEINTMAJORREV — Family Major Release Revision
    [15:8] WLANBITDEINTMINORREV — Core Minor Release Revision
    [7:0] WLANBITDEINTMAINTENANCEREV — Maintenance Release Revision
0x13000 WLAN_DEPARSER group — Unspecified
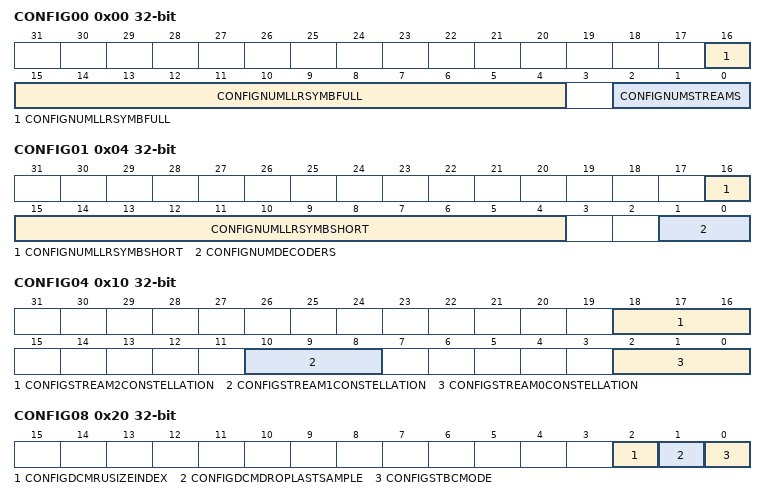
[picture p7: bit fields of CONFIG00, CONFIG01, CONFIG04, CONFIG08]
  0x00 CONFIG00 — WLAN DEPARSER CONFIG 00
    [16:4] CONFIGNUMLLRSYMBFULL — Number of LLRs per OFDM symbol.
    [2:0] CONFIGNUMSTREAMS — The number of Input Streams that are active to process OFDM symbols for the current data stream configuration.Unsigned value with possible range of 0-7.Valid values are below:Note: The valid values above will be restricted if the Wireless LAN Stream Deparser has fewer than four Stream Input ports available.
      0=Reserve (This is reserved.); 1=One Stream Input active. Deparser will read input LLRs from Stream Input0 only.; 2=Two Stream Inputs active.Deparser will read input LLRs from Stream Inputs 0 and 1; 3=Three Stream Inputs active.Deparser will read input LLRs from Stream Inputs 0, 1 and 2; 4=Four Stream Inputs active. Deparser will read input LLRs from Stream Inputs 0, 1, 2 and 3.; 5=Reserve5 (This is reserved.); 6=Reserve6 (This is reserved.); 7=Reserve7 (This is reserved.)
  0x04 CONFIG01 — WLAN DEPARSER CONFIG 01
    [16:4] CONFIGNUMLLRSYMBSHORT — Number of LLRs per OFDM symbol : last symbol or last pair for STBC.
    [1:0] CONFIGNUMDECODERS — The number of Decoders that are needed to process OFDM symbols for the current data stream configuration.Unsigned value with possible range of 0-3.Valid values are below:Note: The valid values above will be restricted if the Wireless LAN Stream Deparser has fewer than two Decoder Output ports available.
      0=Reserve (This is reserved.); 1=One Decoder output active.Output OFDM symbols to Decoder 0 output only; 2=Two Decoder outputs active.Output OFDM symbols to Decoder 0 and Decoder 1 outputs; 3=Reserve3 (This is reserved.)
  0x08 CONFIG02 — WLAN DEPARSER CONFIG 02
    [8:0] CONFIGNUMSUBCARRIERS — The number of Sub Carriers that the Stream Deparser should process for each OFDM symbol of the current data stream configuration.Unsigned value with possible range of 0-511.The valid values for this register are the results of the formula below when derived using the valid values for each element of the formula.All other values are reserved and should not be used.The 32-bit inputs to the Stream Deparser carry up to 4 LLRs per clock, which varies according to the modulation scheme used by each Stream Input.When the Stream Deparser processes one sub-carrier (as defined by this register) it processes one 32-bit word of LLRs from the selected Stream Input.Thus this register defines the number of32-bit words that need to be processed on each Stream Input.This value is also used by the STBC Mux to detect OFDM symbol boundaries - which occur once the STBC mux has processed the number of 32-bit words defined by this register.The value written into this register is calculated using the following formula:(N_SC * Constellation factor) / N_ESWhere:N_SC is the number of Sub-Carriers in each OFDM symbol, i.e. 48, 52, 108 or 234N_ES is the number of Decoder outputs programmed in CONFIG_NUM_DECODERS, i.e. 1 or 2Constellation factor is 1 for BPSK modulation and 2 for non BPSK modulation schemesNote that if BPSK is selected on any Stream Input, other active Stream Inputs can only be set to BPSK modulation.Configuring the active Stream Inputs for a mix of BPSK and non-BPSK Modulation schemes is not valid.
  0x0C CONFIG03 — WLAN DEPARSER CONFIG 03
    [23:0] CONFIGNUMOFDMSYMBOLS — Number of OFDM symbols to process.
  0x10 CONFIG04 — WLAN DEPARSER CONFIG 04
    [18:16] CONFIGSTREAM2CONSTELLATION — This defines the Constellation in use on Stream 2 Input port for each Sub-Carrier.The programming convention for this field is the same as given for field CONFIG_STREAM_0_CONSTELLATION.
    [10:8] CONFIGSTREAM1CONSTELLATION — This defines the Constellation in use on Stream 1 Input port for each Sub-Carrier.The programming convention for this field is the same as given for field CONFIG_STREAM_0_CONSTELLATION.
    [2:0] CONFIGSTREAM0CONSTELLATION — This defines the Constellation in use on Stream 0 Input port for each Sub-Carrier.The value in this field represents the value Nbpsc/2 (with a minimum value of 1) for the Constellation type in use on this Stream Input.The valid values for this field are determined by the index below.All other values are reserved and should not be used.Note that if BPSK is selected on any Stream Input, other active Stream Inputs can only be set to BPSK modulation.Configuring the active Stream Inputs for a mix of BPSK and non-BPSK Modulation schemes is not valid.
      0=BPSK = 1 LLRper Sub-Carrier; 1=QPSK = 1 LLRper Sub-Carrier; 2=16-QAM = 2 LLRs per Sub-Carrier; 3=64-QAM = 3 LLRs per Sub-Carrier; 4=256-QAM = 4 LLRs per Sub-Carrier
  0x14 CONFIG05 — WLAN DEPARSER CONFIG 05
    [2:0] CONFIGSTREAM3CONSTELLATION — This defines the Constellation in use on Stream 3 Input port for each Sub-Carrier.The programming convention for this field is the same as given for field CONFIG_STREAM_0_CONSTELLATION.
  0x20 CONFIG08 — WLAN DEPARSER CONFIG 08
    [2] CONFIGDCMRUSIZEINDEX — RU size used when CONFIG_DCM_DROP_LAST_SAMPLE is set.0x0: 106 tone0x1: 242 tone
    [1] CONFIGDCMDROPLASTSAMPLE — Enable dropping last sample of each OFDM symbol when DCM is enabled, MCS is 0, BCC FEC type and 242 or 106 tone RU type is configured (53 to 64)
    [0] CONFIGSTBCMODE — This register is used to set the Deparser into STBC mode.0x0: Operate Stream Deparser in normal mode (with NO STBC muxing)0x1: Operate Stream Deparser with STBC muxing enabledIn this mode the STBC muxing is enabled in the Wireless LAN Stream Deparser.The way this mode operates is detailed fully in the Wireless LAN Stream Deparser TRM.When STBC mode is selected the registers CONFIG_STBC_LLRS_PER_OFDM_SYMBOL_[0/1] must be programmed according to the descriptions in those registers.Note 1. STBC Mode is only valid for the configurations below:CONFIG_NUM_STREAMS (Nss) = 1: Input data expected on Stream Inputs 0 and 1 (STBC Mux routes data to Deparser processing core Input 0)CONFIG_NUM_STREAMS (Nss) = 2: Input data expected on Stream Inputs 0, 1, 2, and 3 (STBC Mux routes data to Deparser processing core Inputs 0 and 1)Other values in CONFIG_NUM_STREAMS are not valid with STBC mode.Note 2. STBC Mode is only available when input generic N_SS (NUM_WIFI_SS) >= 2 (to support STBC when Nss=1)or input generic N_SS (NUM_WIFI_SS) >= 4 (to support STBC when Nss=[1|2])
  0x24 OUTPUTPACKERNUMLLRSLSBS — WLAN DEPARSER OUTPUT PACKER NUM LLRS LSBS
    [23:0] CONFIGOUTPUTPACKERNUMLLRSLSBS — Number of LLRs in the packet (24 LSBs).Used by the output packer to flush LLRs at the end of the packet.When zero, no flushing will be performed.
  0x28 OUTPUTPACKERNUMLLRSMSBS — WLAN DEPARSER OUTPUT PACKER NUM LLRS MSBS
    [11:0] CONFIGOUTPUTPACKERNUMLLRSMSBS — Number of LLRs in the packet (12 MSBs).Used by the output packer to flush LLRs at the end of the packet.When zero, no flushing will be performed.
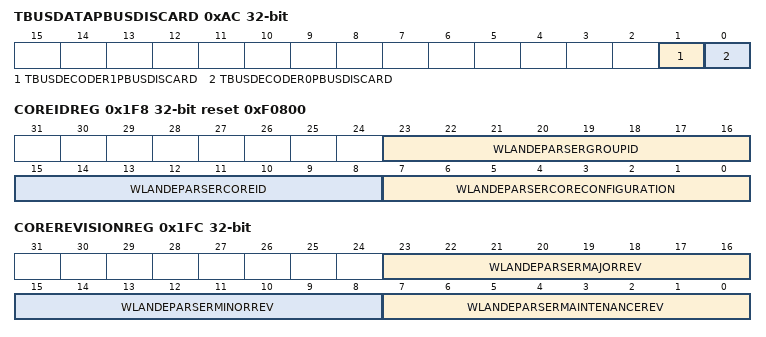
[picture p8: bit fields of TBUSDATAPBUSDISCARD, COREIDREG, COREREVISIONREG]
  0xAC TBUSDATAPBUSDISCARD — WLAN DEPARSER TBUS DATA PBUS DISCARD
    [1] TBUSDECODER1PBUSDISCARD — Set this register to '1' to discard the output from the T-Bus Read component that routes data from the Decoder 1 Output to the T-Bus.This register will only discard output when register field TBUS_DECODER1_ROUTING = 1 (i.e. when routing to the P-Bus debug registers).
    [0] TBUSDECODER0PBUSDISCARD — Set this register to '1' to discard the output from the T-Bus Read component that routes data from the Decoder 0 Output to the T-Bus.This register will only discard output when register field TBUS_DECODER0_ROUTING = 1 (i.e. when routing to the P-Bus debug registers).
  0x1F0 SWRESET — WLAN DEPARSER SW RESET
    [23] SWRESET — Wireless LAN Stream Deparser, Software Reset register SW_RESETThis register provides a means for resetting all the logic in the Wireless LAN Stream Deparser block.The register is sticky so any reset has to be cleared manually.In other words, any reset applied with this register will NOT automatically clear; it must be manually cleared by writing '0' to this register.This software reset register will reset all logic in the Wireless LAN Stream Deparser including:i. T-Bus Write ports (input data to Stream Input Ports)ii.T-Bus Read ports (output data from Decoder Output Ports)iii. The Wireless LAN Stream Deparser processing coreiv.The STBC MultiplexerIt WILL NOT reset the wlan_deparser_regwrap Register Block Wrapper which contains the generated register bank.If the wlan_deparser_regwrap needs to be reset then the entire Wireless LAN Stream Deparser must be reset using the software reset control in the UCCP_CORE registers.Alternatively a hardware reset can be performed.
      values as WLAN_BIT_DEINT.SWRESET.SWRESET
  0x1F8 COREIDREG ro reset 0xF0800 — WLAN DEPARSER CORE ID REG
    [23:16] WLANDEPARSERGROUPID — Identifies core as part of an IMG IP family group.[0x0F = UCC].
    [15:8] WLANDEPARSERCOREID — Identifies the member of the IP group. [0x08 = Wireless LAN Stream Deparser (WLAN_DEPARSER)]
    [7:0] WLANDEPARSERCORECONFIGURATION — Configuration of the core.
  0x1FC COREREVISIONREG ro — WLAN DEPARSER CORE REVISION REG
    [23:16] WLANDEPARSERMAJORREV — Family Major Release Revision
    [15:8] WLANDEPARSERMINORREV — Core Minor Release Revision
    [7:0] WLANDEPARSERMAINTENANCEREV — Maintenance Release Revision
